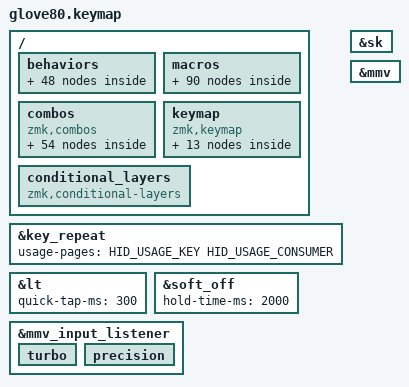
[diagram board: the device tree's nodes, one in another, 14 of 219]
/*
 * Copyright (c) 2020 The ZMK Contributors
 *
 * SPDX-License-Identifier: MIT
 *  
 * Important notes, labels cannot be long
 */
// Mouse speed (precision mode divides by 3 via scaler)

#define ZMK_POINTING_DEFAULT_MOVE_VAL 500

#include <input/processors.dtsi>
#include <behaviors.dtsi>
#include <dt-bindings/zmk/bt.h>
#include <dt-bindings/zmk/keys.h>
#include <dt-bindings/zmk/outputs.h>
#include <dt-bindings/zmk/pointing.h>
#include <dt-bindings/zmk/rgb.h>

#define HYPER LC(LS(LG(LALT)))

// layers

&key_repeat { usage-pages = <HID_USAGE_KEY HID_USAGE_CONSUMER>; };

&sk {
    quick-release;
    release-after-ms = <2000>;
};

&lt { quick-tap-ms = <300>; };

&soft_off { hold-time-ms = <2000>; };

/ {
    behaviors {
        // For the "layer" key, it'd nice to be able to use it as either a shift or a toggle.
        // Configure it as a tap dance, so the first tap (or hold) is a &mo and the second tap is a &to

        magic: magic_hold_tap {
            compatible = "zmk,behavior-hold-tap";
            label = "MAGIC_HOLD_TAP";
            #binding-cells = <2>;
            flavor = "tap-preferred";
            tapping-term-ms = <200>;
            bindings = <&mo>, <&rgb_ug_status_macro>;
        };

        // Play / Next / Prev button

        play_next_prev_td: play_next_prev_td {
            compatible = "zmk,behavior-tap-dance";
            label = "PLAY_NEXT_PREV_TD";
            #binding-cells = <0>;
            bindings = <&kp C_PP>, <&kp C_NEXT>, <&kp C_PREV>;
        };

        // Caps word and dt for CAPSLOCK 
        /* Selection behaviours morphs
         *
         * This behaviours select text in a particular way.
         * They default to selecting to the right, but when shifted, they go to the left
         *
         * They depend on the 'selection' macros
         */

        select_word: select_word {
            compatible = "zmk,behavior-mod-morph";
            #binding-cells = <0>;
            label = "SELECT_WORD";
            bindings = <&select_word_right>, <&select_word_left>;

            mods = <(MOD_LSFT|MOD_RSFT)>;
        };

        extend_word: extend_word {
            compatible = "zmk,behavior-mod-morph";
            #binding-cells = <0>;
            bindings = <&extend_word_right>, <&extend_word_left>;

            mods = <(MOD_LSFT|MOD_RSFT)>;
        };

        extend_line: extend_line {
            compatible = "zmk,behavior-mod-morph";
            #binding-cells = <0>;
            bindings = <&extend_line_right>, <&extend_line_left>;

            mods = <(MOD_LSFT|MOD_RSFT)>;
        };

        select_line: select_line {
            compatible = "zmk,behavior-mod-morph";
            #binding-cells = <0>;
            bindings = <&select_line_right>, <&select_line_left>;

            mods = <(MOD_LSFT|MOD_RSFT)>;
        };

        sk_mo: sk_mo {
            compatible = "zmk,behavior-hold-tap";
            label = "SK_MO";
            bindings = <&mo>, <&sk>;

            #binding-cells = <2>;
            tapping-term-ms = <200>;
        };

        // 1t: selet all, 2t: cut all, 3t: copy all

        selec_all_copy_all_tp: selec_all_copy_all_tp {
            compatible = "zmk,behavior-tap-dance";
            label = "SELEC_ALL_COPY_ALL_TP";
            #binding-cells = <0>;
            bindings = <&kp LC(A)>, <&select_all_cut>, <&select_and_copy_all>;
        };

        // dt the ' to screenshot (convinient)
        // Hold like shift key, and tap to toggle it
        // 1t: show screen, 2t: toggle camera

        mst_show_screen_vid_td: mst_show_screen_vid_td {
            compatible = "zmk,behavior-tap-dance";
            label = "Show screen and toggle video";
            #binding-cells = <0>;
            bindings = <&mst_show_screen>, <&kp LS(LC(O))>;
        };

        // 1t: go to call window, 2t: answer call from toast, 3t: Call someone from the chat

        mst_call_cmds_td: mst_call_cmds_td {
            compatible = "zmk,behavior-tap-dance";
            label = "MST_CALL_CMDS_TD";
            #binding-cells = <0>;
            bindings = <&mst_go_mst_meeting>, <&mst_join_call>, <&kp LA(LS(A))>;
        };

        layer_mo_tog: layer_mo_tog {
            compatible = "zmk,behavior-hold-tap";
            label = "LAYER_MO_TOG";
            bindings = <&mo>, <&tog>;

            #binding-cells = <2>;
            tapping-term-ms = <200>;
            flavor = "balanced";
        };

        // 1t: reply to selcted message, 2t: reply to last message
        // 1t: react happy to selcted message, 2t: react happy to last message

        mst_react_td: mst_react_td {
            compatible = "zmk,behavior-tap-dance";
            label = "MST_REACT_TD";
            #binding-cells = <0>;
            bindings =
                <&mst_react_happy>,
                <&mst_react_heart>,
                <&mst_react_lol>,
                <&mst_react_surprise>;

            tapping-term-ms = <300>;
        };

        /* 
        * Home row mods
        *
        * This mods allow you to put modifiers in the home row, and be comfortable. Inspiration from: https://github.com/urob/zmk-config
        *
        * 1. Do not allow same hand mods (avoids collitions from the same hand)
        * 2. Quick tapping for tap hold behavior
        * 3. Hold trigger on release allows you to write fast without activating false positives
        *
        * There is a left and right version of the behaviour. You must put them accordingly
        */

        hrm_left: hrm_left {
            compatible = "zmk,behavior-hold-tap";
            label = "HRM_LEFT";
            bindings = <&kp>, <&kp>;

            #binding-cells = <2>;
            tapping-term-ms = <280>;
            quick-tap-ms = <200>;
            flavor = "balanced";
            require-prior-idle-ms = <175>;
            hold-trigger-key-positions = <55 56 57 72 73 74 40 58 28 16 6 7 8 9 18 19 20 21 30 31 32 33 42 43 44 45 60 61 62 63 76 77 78 79 5 6 17 18 29 30 41 42 59 60 75 76 52 53 54 70 71 69>;
            hold-trigger-on-release;
        };

        hrm_right: hrm_right {
            compatible = "zmk,behavior-hold-tap";
            label = "HRM_RIGHT";
            bindings = <&kp>, <&kp>;

            #binding-cells = <2>;
            tapping-term-ms = <280>;
            quick-tap-ms = <200>;
            flavor = "balanced";
            require-prior-idle-ms = <175>;
            hold-trigger-key-positions = <0 2 3 4 14 13 12 10 11 1 22 23 35 34 46 47 64 65 66 67 68 69 70 71 54 53 52 50 48 49 37 36 24 25 26 15 39 38 27 51 55 56 57 74 73 72>;
            hold-trigger-on-release;
        };

        // Similar to HRM but in thumbs for custom behaviour

        lt_thumbs_keys: lt_thumbs_keys {
            compatible = "zmk,behavior-hold-tap";
            label = "LT_THUMBS_KEYS";
            bindings = <&mo>, <&kp>;

            #binding-cells = <2>;
            tapping-term-ms = <175>;
            quick-tap-ms = <300>;
            flavor = "tap-preferred";
        };

        paste_copy_cut_td: paste_copy_cut_td {
            compatible = "zmk,behavior-tap-dance";
            label = "PASTE_COPY_CUT_TD";
            #binding-cells = <0>;
            bindings = <&paste>, <&copy>, <&cut>;
        };

        lock_td: lock_td {
            compatible = "zmk,behavior-tap-dance";
            label = "LOCK_TD";
            #binding-cells = <0>;
            bindings = <&kp LG(L)>, <&kp LG(ESCAPE)>;
        };

        vim_norm_delete: vim_norm_delete {
            compatible = "zmk,behavior-tap-dance";
            label = "VIM_NORM_DELETE";
            #binding-cells = <0>;
            bindings = <&kp DELETE>, <&del_line>;
        };

        vim_norm_a: vim_norm_a {
            compatible = "zmk,behavior-mod-morph";
            label = "VIM_NORM_A";
            bindings = <&vim_kp_exit_norm RIGHT>, <&vim_kp_exit_norm END>;

            #binding-cells = <0>;
            mods = <(MOD_RSFT|MOD_LSFT)>;
        };

        vim_norm_i: vim_norm_i {
            compatible = "zmk,behavior-mod-morph";
            label = "VIM_NORM_I";
            bindings = <&tog 0>, <&vim_kp_exit_norm HOME>;

            #binding-cells = <0>;
            mods = <(MOD_RSFT|MOD_LSFT)>;
        };

        vim_norm_c: vim_norm_c {
            compatible = "zmk,behavior-mod-morph";
            label = "VIM_NORM_C";
            bindings = <&vim_norm_c_inner_word>, <&vim_c_del_line>;

            #binding-cells = <0>;
            mods = <(MOD_RSFT|MOD_LSFT)>;
        };

        vim_norm_v: vim_norm_v {
            compatible = "zmk,behavior-mod-morph";
            label = "VIM_NORM_V";
            bindings = <&vim_norm_v_kp>, <&vim_norm_V_kp>;

            #binding-cells = <0>;
            mods = <(MOD_RSFT|MOD_LSFT)>;
        };

        app_switcher_td: app_switcher_td {
            compatible = "zmk,behavior-tap-dance";
            label = "APP_SWITCHER_TD";
            #binding-cells = <0>;
            bindings = <&app_switcher>, <&app_switcher_killer>;
        };

        sk_shift_caps_word_caps_td: sk_shift_caps_word_caps_td {
            compatible = "zmk,behavior-tap-dance";
            label = "SK_SHIFT_CAPS_WORD_CAPS_TD";
            #binding-cells = <0>;
            bindings = <&sk RIGHT_SHIFT>, <&caps_word>, <&kp CAPSLOCK>;
        };

        better_slash: better_slash {
            compatible = "zmk,behavior-mod-morph";
            label = "BETTER_SLASH";
            bindings = <&kp SLASH>, <&kp BACKSLASH>;

            #binding-cells = <0>;
            mods = <(MOD_LALT|MOD_RALT)>;
        };

        // Shift HRM: faster timing (175ms vs 200ms) because index fingers naturally move faster
        // than other fingers. Lower require-prior-idle (150ms) for same reason.

        hmr_shift_left: hmr_shift_left {
            compatible = "zmk,behavior-hold-tap";
            label = "HMR_SHIFT_LEFT";
            bindings = <&kp>, <&kp>;

            #binding-cells = <2>;
            tapping-term-ms = <200>;
            quick-tap-ms = <175>;
            flavor = "balanced";
            require-prior-idle-ms = <150>;
            hold-trigger-key-positions = <55 56 57 72 73 74 40 58 28 16 6 7 8 9 18 19 20 21 30 31 32 33 42 43 44 45 60 61 62 63 76 77 78 79 5 6 17 18 29 30 41 42 59 60 75 76 52 53 54 70 71 69>;
            hold-trigger-on-release;
        };

        hmr_shift_right: hmr_shift_right {
            compatible = "zmk,behavior-hold-tap";
            label = "HMR_SHIFT_RIGHT";
            bindings = <&kp>, <&kp>;

            #binding-cells = <2>;
            tapping-term-ms = <200>;
            quick-tap-ms = <175>;
            flavor = "balanced";
            require-prior-idle-ms = <150>;
            hold-trigger-key-positions = <55 56 57 72 73 74 52 53 54 70 71 69 0 1 2 3 4 10 11 12 13 14 15 22 23 24 25 26 27 34 35 36 37 38 39 46 47 48 49 50 51 52 53 54 64 65 66 67 68 69 70 71>;
            hold-trigger-on-release;
        };

        mst_goback_call_mt: mst_goback_call_mt {
            compatible = "zmk,behavior-hold-tap";
            label = "MST_GOBACK_CALL_MT";
            bindings = <&go_call_unmute_mute_go_back>, <&kp>;

            #binding-cells = <2>;
            flavor = "tap-preferred";
            tapping-term-ms = <125>;
        };

        mst_chatlist_go_unread_mute_td: mst_chatlist_go_unread_mute_td {
            compatible = "zmk,behavior-tap-dance";
            label = "MST_CHATLIST_GO_UNREAD_MUTE_TD";
            #binding-cells = <0>;
            bindings =
                <&kp LC(L)>,
                <&mst_tog_unread_chat>,
                <&mst_tog_mute_chat>;

            tapping-term-ms = <300>;
        };

        hold_bt_0: hold_bt_0 {
            compatible = "zmk,behavior-hold-tap";
            label = "HOLD_BT_0";
            bindings = <&bt_0>, <&kp>;

            #binding-cells = <2>;
            tapping-term-ms = <200>;
            quick-tap-ms = <300>;
            require-prior-idle-ms = <200>;
            flavor = "tap-preferred";
        };

        hold_bt_2: hold_bt_2 {
            compatible = "zmk,behavior-hold-tap";
            label = "HOLD_BT_2";
            bindings = <&bt_2>, <&kp>;

            #binding-cells = <2>;
            tapping-term-ms = <200>;
            quick-tap-ms = <300>;
            require-prior-idle-ms = <200>;
            flavor = "tap-preferred";
        };

        hold_bt_1: hold_bt_1 {
            compatible = "zmk,behavior-hold-tap";
            label = "HOLD_BT_1";
            bindings = <&bt_1>, <&kp>;

            #binding-cells = <2>;
            tapping-term-ms = <200>;
            quick-tap-ms = <300>;
            require-prior-idle-ms = <200>;
            flavor = "tap-preferred";
        };

        lpar_lt: lpar_lt {
            compatible = "zmk,behavior-mod-morph";
            label = "LPAR_LT";
            bindings = <&kp LEFT_PARENTHESIS>, <&kp LESS_THAN>;

            #binding-cells = <0>;
            mods = <(MOD_LSFT|MOD_RSFT)>;
        };

        rpar_gt: rpar_gt {
            compatible = "zmk,behavior-mod-morph";
            label = "RPAR_GT";
            bindings = <&kp RIGHT_PARENTHESIS>, <&kp GREATER_THAN>;

            #binding-cells = <0>;
            mods = <(MOD_LSFT|MOD_RSFT)>;
        };

        lbra_cur: lbra_cur {
            compatible = "zmk,behavior-mod-morph";
            label = "LBRA_CUR";
            bindings = <&kp LEFT_BRACKET>, <&kp LEFT_BRACE>;

            #binding-cells = <0>;
            mods = <(MOD_LSFT|MOD_RSFT)>;
        };

        rbra_cur: rbra_cur {
            compatible = "zmk,behavior-mod-morph";
            label = "RBRA_CUR";
            bindings = <&kp RIGHT_BRACKET>, <&kp RIGHT_BRACE>;

            #binding-cells = <0>;
            mods = <(MOD_LSFT|MOD_RSFT)>;
        };

        hrm_right_lpar: hrm_right_lpar {
            compatible = "zmk,behavior-hold-tap";
            label = "HRM_RIGHT_LPAR";
            bindings = <&kp>, <&lpar_lt>;

            #binding-cells = <2>;
            tapping-term-ms = <280>;
            quick-tap-ms = <200>;
            flavor = "balanced";
            require-prior-idle-ms = <150>;
            hold-trigger-key-positions = <0 2 3 4 14 13 12 10 11 1 22 23 35 34 46 47 64 65 66 67 68 69 70 71 54 53 52 50 48 49 37 36 24 25 26 15 39 38 27 51 55 56 57 74 73 72>;
            hold-trigger-on-release;
        };

        hrm_right_rpar: hrm_right_rpar {
            compatible = "zmk,behavior-hold-tap";
            label = "HRM_RIGHT_RPAR";
            bindings = <&kp>, <&rpar_gt>;

            #binding-cells = <2>;
            tapping-term-ms = <280>;
            quick-tap-ms = <200>;
            flavor = "balanced";
            require-prior-idle-ms = <150>;
            hold-trigger-key-positions = <0 2 3 4 14 13 12 10 11 1 22 23 35 34 46 47 64 65 66 67 68 69 70 71 54 53 52 50 48 49 37 36 24 25 26 15 39 38 27 51 55 56 57 74 73 72>;
            hold-trigger-on-release;
        };

        better_backspace: better_backspace {
            compatible = "zmk,behavior-mod-morph";
            label = "BETTER_BACKSPACE";
            bindings = <&kp BACKSPACE>, <&kp DELETE>;

            #binding-cells = <0>;
            mods = <(MOD_LSFT|MOD_RSFT)>;
            keep-mods = <(MOD_LSFT)>;
        };

        lt_thumb_backspace: lt_thumb_backspace {
            compatible = "zmk,behavior-hold-tap";
            label = "LT_THUMB_BACKSPACE";
            bindings = <&mo>, <&better_backspace>;

            #binding-cells = <2>;
            tapping-term-ms = <175>;
            quick-tap-ms = <300>;
            flavor = "tap-preferred";
        };

        better_space: better_space {
            compatible = "zmk,behavior-mod-morph";
            label = "BETTER_SPACE";
            bindings = <&kp SPACE>, <&auto_cap_dot>;

            #binding-cells = <0>;
            mods = <(MOD_LSFT)>;
            keep-mods = <(MOD_LCTL|MOD_LALT|MOD_LGUI|MOD_RCTL|MOD_RSFT|MOD_RALT|MOD_RGUI)>;
        };

        lt_thumb_better_space: lt_thumb_better_space {
            compatible = "zmk,behavior-hold-tap";
            label = "LT_THUMB_BETTER_SPACE";
            bindings = <&mo>, <&better_space>;

            #binding-cells = <2>;
            tapping-term-ms = <175>;
            quick-tap-ms = <300>;
            flavor = "tap-preferred";
        };

        copy_cut_td: copy_cut_td {
            compatible = "zmk,behavior-tap-dance";
            label = "COPY_CUT_TD";
            #binding-cells = <0>;
            bindings = <&copy>, <&cut>;
        };

        lt_thumb_gresc: lt_thumb_gresc {
            compatible = "zmk,behavior-hold-tap";
            label = "LT_THUMB_GRESC";
            bindings = <&mo>, <&gresc>;

            #binding-cells = <2>;
            tapping-term-ms = <175>;
            quick-tap-ms = <300>;
            flavor = "tap-preferred";
        };

        lt_thumb_shift_td: lt_thumb_shift_td {
            compatible = "zmk,behavior-hold-tap";
            label = "LT_THUMB_SHIFT_TD";
            bindings = <&mo>, <&sk_shift_caps_word_caps_td>;

            #binding-cells = <2>;
            tapping-term-ms = <175>;
            quick-tap-ms = <300>;
            flavor = "tap-preferred";
        };

        am_hrm_behaviour: am_hrm_behaviour {
            compatible = "zmk,behavior-hold-tap";
            label = "AM_HRM_BEHAVIOUR";
            bindings = <&kp>, <&hour_am>;

            #binding-cells = <2>;
            tapping-term-ms = <280>;
            quick-tap-ms = <200>;
            flavor = "balanced";
            require-prior-idle-ms = <150>;
            hold-trigger-key-positions = <55 56 57 72 73 74 40 58 28 16 6 7 8 9 18 19 20 21 30 31 32 33 42 43 44 45 60 61 62 63 76 77 78 79 5 6 17 18 29 30 41 42 59 60 75 76 52 53 54 70 71 69>;
            hold-trigger-on-release;
        };

        mst_gocall_goback_mt: mst_gocall_goback_mt {
            compatible = "zmk,behavior-hold-tap";
            label = "MST_GOCALL_GOBACK_MT";
            bindings = <&go_call_unmute_mute_go_back>, <&mst_go_call_unmute>;

            #binding-cells = <2>;
            flavor = "tap-preferred";
            tapping-term-ms = <125>;
        };

        mouse_gresc_td: mouse_gresc_td {
            compatible = "zmk,behavior-tap-dance";
            label = "MOUSE_GRESC_TD";
            #binding-cells = <0>;
            tapping-term-ms = <150>;
            bindings = <&lt_thumb_gresc 8 0>, <&tog 8>;
        };
    };

    macros {
        // Bluethoot profile macros, DO NOT TOUCH

        rgb_ug_status_macro: rgb_ug_status_macro_0 {
            label = "RGB_UG_STATUS";
            compatible = "zmk,behavior-macro";
            #binding-cells = <0>;
            bindings = <&rgb_ug RGB_STATUS>;
        };

        bt_0: bt_profile_macro_0 {
            label = "BT_0";
            compatible = "zmk,behavior-macro";
            #binding-cells = <0>;
            bindings = <&out OUT_BLE &bt BT_SEL 0>;
        };

        bt_1: bt_profile_macro_1 {
            label = "BT_1";
            compatible = "zmk,behavior-macro";
            #binding-cells = <0>;
            bindings = <&out OUT_BLE &bt BT_SEL 1>;
        };

        bt_2: bt_profile_macro_2 {
            label = "BT_2";
            compatible = "zmk,behavior-macro";
            #binding-cells = <0>;
            bindings = <&out OUT_BLE &bt BT_SEL 2>;
        };

        bt_3: bt_profile_macro_3 {
            label = "BT_3";
            compatible = "zmk,behavior-macro";
            #binding-cells = <0>;
            bindings = <&out OUT_BLE &bt BT_SEL 3>;
        };

        // Selection Macros

        select_none: select_none {
            label = "SN";
            compatible = "zmk,behavior-macro";
            #binding-cells = <0>;
            bindings = <&kp DOWN &kp UP &kp RIGHT &kp LEFT>;
        };

        select_word_right: select_word_right {
            compatible = "zmk,behavior-macro";
            label = "SELECT_WORD_RIGHT";
            #binding-cells = <0>;
            bindings = <&kp LC(RIGHT) &kp LC(LEFT) &kp LC(LS(RIGHT))>;
        };

        select_word_left: select_word_left {
            compatible = "zmk,behavior-macro";
            label = "SELECT_WORD_LEFT";
            #binding-cells = <0>;
            bindings = <&kp LC(LEFT_ARROW) &kp LC(RIGHT) &kp LC(LS(LEFT_ARROW))>;
        };

        extend_word_right: extend_word_right {
            compatible = "zmk,behavior-macro";
            #binding-cells = <0>;
            bindings = <&kp LS(LC(RIGHT))>;
            label = "EXTEND_WORD_RIGHT";
        };

        extend_word_left: extend_word_left {
            compatible = "zmk,behavior-macro";
            #binding-cells = <0>;
            bindings = <&kp LS(LC(LEFT_ARROW))>;
            label = "EXTEND_WORD_LEFT";
        };

        select_line_right: select_line_right {
            compatible = "zmk,behavior-macro";
            #binding-cells = <0>;
            bindings = <&kp HOME &kp LS(END)>;
            label = "SELECT_LINE_RIGHT";
        };

        select_line_left: select_line_left {
            compatible = "zmk,behavior-macro";
            #binding-cells = <0>;
            bindings = <&kp END &kp LS(HOME)>;
            label = "SELECT_LINE_LEFT";
        };

        extend_line_left: extend_line_left {
            compatible = "zmk,behavior-macro";
            #binding-cells = <0>;
            bindings = <&kp LS(UP) &kp LS(HOME)>;
            label = "EXTEND_LINE_LEFT";
        };

        extend_line_right: extend_line_right {
            compatible = "zmk,behavior-macro";
            #binding-cells = <0>;
            bindings = <&kp LS(DOWN) &kp LS(END)>;
            label = "EXTEND_LINE_RIGHT";
        };

        // Text manipulation

        undo: undo {
            compatible = "zmk,behavior-macro";
            #binding-cells = <0>;
            bindings = <&kp RC(Z)>;
            label = "UNDO";
        };

        redo: redo {
            compatible = "zmk,behavior-macro";
            #binding-cells = <0>;
            bindings = <&kp LC(Y)>;
            label = "REDO";
        };

        cut: cut {
            compatible = "zmk,behavior-macro";
            #binding-cells = <0>;
            bindings = <&kp LC(X)>;
            label = "CUT";
        };

        paste: paste {
            compatible = "zmk,behavior-macro";
            #binding-cells = <0>;
            bindings = <&kp LC(V)>;
            label = "PASTE";
        };

        copy: copy {
            compatible = "zmk,behavior-macro";
            #binding-cells = <0>;
            bindings = <&kp LC(C)>;
            label = "COPY";
        };

        my_email: my_email {
            compatible = "zmk,behavior-macro";
            #binding-cells = <0>;
            bindings = <&kp E &kp D &kp Y &kp G &kp O &kp M &kp E &kp Z &kp G &kp G &kp N4 &kp AT &kp G &kp M &kp A &kp I &kp L &kp DOT &kp C &kp O &kp M>;
            label = "MY_EMAIL";
        };

        win_desktop_right: win_right_desktop {
            compatible = "zmk,behavior-macro";
            #binding-cells = <0>;
            bindings = <&kp LC(LG(RIGHT))>;
            label = "WIN_RIGHT_DESKTOP";
        };

        win_desktop_left: win_desktop_left {
            compatible = "zmk,behavior-macro";
            #binding-cells = <0>;
            bindings = <&kp LC(LG(LEFT))>;
            label = "WIN_DESKTOP_LEFT";
        };

        close_app: close_app {
            compatible = "zmk,behavior-macro";
            #binding-cells = <0>;
            bindings = <&kp LA(F4)>;
            label = "CLOSE_APP";
        };

        select_and_copy_all: select_and_copy_all {
            compatible = "zmk,behavior-macro";
            #binding-cells = <0>;
            bindings = <&kp LC(A) &kp LC(C) &kp RIGHT>;
            label = "SELECT_AND_COPY_ALL";
        };

        select_all_cut: select_all_cut {
            compatible = "zmk,behavior-macro";
            #binding-cells = <0>;
            bindings = <&kp LC(A) &kp LC(X) &kp RIGHT>;
            label = "SELECT_ALL_CUT";
        };

        // Microsoft Teams (mst) layer macros

        mst_available: mst_available {
            compatible = "zmk,behavior-macro";
            #binding-cells = <0>;
            bindings =
                <&kp LC(E) &kp SLASH &kp A &kp V &kp A &kp I &kp L &kp A &kp B &kp L>,
                <&macro_wait_time 200>,
                <&kp E &kp ENTER>;

            label = "mst_AVAILABLE";
        };

        mst_busy: mst_busy {
            compatible = "zmk,behavior-macro";
            #binding-cells = <0>;
            bindings =
                <&kp LC(E) &kp SLASH &kp B &kp U &kp S>,
                <&macro_wait_time 200>,
                <&kp Y &kp ENTER>;

            label = "mst_BUSY";
        };

        mst_brb: mst_brb {
            compatible = "zmk,behavior-macro";
            #binding-cells = <0>;
            bindings =
                <&kp LC(E) &kp SLASH &kp B &kp R>,
                <&macro_wait_time 200>,
                <&kp B &kp ENTER>;

            label = "mst_BRB";
        };

        mst_offline: mst_offline {
            compatible = "zmk,behavior-macro";
            #binding-cells = <0>;
            bindings =
                <&kp LC(E) &kp SLASH &kp O &kp F &kp F &kp L &kp I &kp N>,
                <&macro_wait_time 200>,
                <&kp E &kp ENTER>;

            label = "mst_OFFLINE";
        };

        mst_away: mst_away {
            compatible = "zmk,behavior-macro";
            #binding-cells = <0>;
            bindings =
                <&kp LC(E) &kp SLASH &kp A &kp W &kp A>,
                <&macro_wait_time 200>,
                <&kp Y &kp ENTER>;

            label = "mst_AWAY";
        };

        mst_go_mst_meeting: mst_go_call {
            compatible = "zmk,behavior-macro";
            #binding-cells = <0>;
            bindings =
                <&kt LEFT_WIN>,
                <&macro_wait_time 100>,
                <&kp N1 &kp NUMBER_1 &kt LEFT_WIN>;

            label = "MST_GO_CALL";
        };

        mst_reply_current_msg: mst_reply_current_msg {
            compatible = "zmk,behavior-macro";
            #binding-cells = <0>;
            bindings = <&kp ENTER &kp LEFT &kp LEFT_ARROW &kp ENTER &tog 3>;
            label = "MST_REPLY_CURRENT_MSG";
        };

        mst_react_happy: mst_react_happy {
            compatible = "zmk,behavior-macro";
            #binding-cells = <0>;
            bindings = <&kp ENTER &kp ENTER &kp ESCAPE>;
            label = "MST_REACT_HAPPY";
        };

        mst_key_exit_mst: mst_key_exit_mst {
            compatible = "zmk,behavior-macro-one-param";
            #binding-cells = <1>;
            bindings = <&macro_param_1to1 &kp MACRO_PLACEHOLDER &tog 3>;
            label = "MST_KEY_EXIT_MST";
        };

        vim_kp_exit_norm: vim_to_insert {
            compatible = "zmk,behavior-macro-one-param";
            #binding-cells = <1>;
            bindings = <&macro_param_1to1 &kp MACRO_PLACEHOLDER &tog 0>;
            label = "VIM_TO_INSERT";
        };

        vim_exit_visual_kp: vim_tog_visual {
            compatible = "zmk,behavior-macro-one-param";
            #binding-cells = <1>;
            bindings = <&kt LEFT_SHIFT &macro_param_1to1 &kp MACRO_PLACEHOLDER &tog 0 &kp RIGHT &kp LEFT_ARROW>;
            label = "VIM_TOG_VISUAL";
        };

        vim_norm_v_kp: vim_enter_visual {
            compatible = "zmk,behavior-macro";
            #binding-cells = <0>;
            bindings = <&tog 0 &kt LEFT_SHIFT>;
            label = "VIM_ENTER_VISUAL";
        };

        mst_go_to_teams: mst_go_to_teams {
            compatible = "zmk,behavior-macro";
            #binding-cells = <0>;
            bindings =
                <&macro_wait_time 100>,
                <&macro_press>,
                <&kp LEFT_WIN>,
                <&macro_tap>,
                <&kp NUMBER_1>,
                <&macro_release>,
                <&kp LEFT_WIN>;

            label = "MST_GO_TO_TEAMS";
        };

        two_kp: dt_kp {
            compatible = "zmk,behavior-macro-two-param";
            #binding-cells = <2>;
            bindings = <&macro_param_1to1 &kp MACRO_PLACEHOLDER &macro_param_2to1 &kp MACRO_PLACEHOLDER>;
            label = "DT_KP";
        };

        del_line: del_line {
            compatible = "zmk,behavior-macro";
            #binding-cells = <0>;
            bindings = <&kp HOME &kp LS(END) &kp LC(X)>;
            label = "DEL_LINE";
        };

        copy_line: copy_line {
            compatible = "zmk,behavior-macro";
            #binding-cells = <0>;
            bindings = <&kp HOME &kp LS(END) &kp LC(C) &kp END>;
            label = "COPY_LINE";
        };

        mo_w_glow: mo_w_glow {
            compatible = "zmk,behavior-macro-two-param";
            #binding-cells = <2>;
            bindings =
                <&macro_wait_time 50>,
                <&macro_tap_time 0>,
                <&macro_press>,
                <&macro_param_1to1 &mo MACRO_PLACEHOLDER>,
                <&macro_tap>,
                <&macro_param_2to2 &rgb_ug RGB_COLOR_HSB_CMD MACRO_PLACEHOLDER>,
                <&macro_pause_for_release>,
                <&macro_release>,
                <&macro_param_1to1 &mo MACRO_PLACEHOLDER>,
                <&macro_tap>,
                <&rgb_ug RGB_OFF>;

            label = "MO_W_GLOW";
        };

        vim_exit_visual_and_norm: vim_exit_visual_norm {
            compatible = "zmk,behavior-macro-one-param";
            #binding-cells = <1>;
            bindings = <&kt LEFT_SHIFT &macro_param_1to1 &kp MACRO_PLACEHOLDER &tog 0 &tog 0 &kp RIGHT &kp LEFT_ARROW>;
            label = "VIM_EXIT_VISUAL_NORM";
        };

        vim_copy_kp: vim_copy_kp {
            compatible = "zmk,behavior-macro";
            #binding-cells = <0>;
            bindings = <&kp LC(C) &kp ESCAPE>;
            label = "VIM_COPY_KP";
        };

        vim_o_kp: vim_o_kp {
            compatible = "zmk,behavior-macro";
            #binding-cells = <0>;
            bindings = <&kp END &kp ENTER &tog 0>;
            label = "VIM_O_KP";
        };

        vim_c_del_line: vim_c_del_line {
            compatible = "zmk,behavior-macro";
            #binding-cells = <0>;
            bindings = <&kp LS(DOWN) &kp LS(END) &kp DEL &tog 0>;
            label = "VIM_C_DEL_LINE";
        };

        vim_norm_c_inner_word: vim_norm_c_inner_word {
            compatible = "zmk,behavior-macro";
            #binding-cells = <0>;
            bindings =
                <&macro_wait_time 100>,
                <&select_word_right &kp DELETE &tog 0>;

            label = "VIM_NORM_C_INNER_WORD";
        };

        vim_norm_V_kp: vim_V_kp {
            compatible = "zmk,behavior-macro";
            #binding-cells = <0>;
            bindings =
                <&tog 0>,
                <&macro_wait_time 100>,
                <&kp HOME>,
                <&macro_wait_time 30>,
                <&kt LEFT_SHIFT &kp END>;

            label = "VIM_V_KP";
        };

        app_switcher: app_switcher {
            compatible = "zmk,behavior-macro";
            #binding-cells = <0>;
            bindings =
                <&macro_press>,
                <&kp LEFT_ALT>,
                <&macro_tap>,
                <&kp TAB>,
                <&macro_pause_for_release>,
                <&macro_release>,
                <&kp LEFT_ALT>;

            label = "APP_SWITCHER";
        };

        mst_join_call: mst_join_call {
            compatible = "zmk,behavior-macro";
            #binding-cells = <0>;
            bindings =
                <&macro_wait_time 2000>,
                <&kp LC(LS(J))>,
                <&macro_wait_time 200>,
                <&macro_press>,
                <&kp LEFT_SHIFT>,
                <&macro_tap>,
                <&kp TAB &kp TAB &kp TAB>,
                <&macro_release>,
                <&kp LEFT_SHIFT>,
                <&macro_tap>,
                <&kp ENTER>;

            label = "MST_JOIN_CALL";
        };

        app_switcher_killer: app_switcher_killer {
            compatible = "zmk,behavior-macro";
            #binding-cells = <0>;
            bindings =
                <&macro_press>,
                <&kp LEFT_ALT>,
                <&macro_tap>,
                <&kp TAB>,
                <&macro_pause_for_release>,
                <&macro_wait_time 100>,
                <&macro_release>,
                <&kp LEFT_ALT>,
                <&macro_tap>,
                <&close_app>;

            label = "APP_SWITCHER_KILLER";
        };

        vim_exit_visual: vim_exit_visual {
            compatible = "zmk,behavior-macro";
            #binding-cells = <0>;
            bindings = <&kt LEFT_SHIFT &tog 0>;
            label = "VIM_EXIT_VISUAL";
        };

        full_screen_window: full_screen_window {
            compatible = "zmk,behavior-macro";
            #binding-cells = <0>;
            bindings =
                <&macro_wait_time 200>,
                <&macro_press>,
                <&kp LEFT_GUI>,
                <&macro_tap>,
                <&kp UP_ARROW &kp UP_ARROW &kp DOWN &kp UP_ARROW>,
                <&macro_release>,
                <&kp LEFT_GUI>;

            label = "FULL_SCREEN_WINDOW";
        };

        go_call_unmute_mute_go_back: go_call_unmute_mute_go_back {
            compatible = "zmk,behavior-macro";
            #binding-cells = <0>;
            bindings =
                <&mst_go_mst_meeting>,
                <&macro_wait_time 30>,
                <&macro_press>,
                <&kp LC(LS(M))>,
                <&macro_pause_for_release>,
                <&macro_release>,
                <&kp LC(LS(M))>,
                <&macro_tap>,
                <&kp LA(TAB)>;

            label = "GO_CALL_UNMUTE_MUTE_GO_BACK";
        };

        mst_tog_unread_chat: mst_tog_red_chat {
            compatible = "zmk,behavior-macro";
            #binding-cells = <0>;
            bindings = <&macro_wait_time 60>, <&kp K_APP &kp DOWN &kp ENTER>;

            label = "MST_TOG_RED_CHAT";
        };

        mst_tog_mute_chat: mst_tog_chat_mute {
            compatible = "zmk,behavior-macro";
            #binding-cells = <0>;
            bindings =
                <&macro_wait_time 60>,
                <&kp K_APP &kp DOWN &kp DOWN &kp DOWN &kp ENTER>;

            label = "MST_TOG_CHAT_MUTE";
        };

        win_move_screen_left: win_move_screen_left {
            compatible = "zmk,behavior-macro";
            #binding-cells = <0>;
            bindings = <&kp LG(LS(LEFT))>;
            label = "WIN_MOVE_SCREEN_LEFT";
        };

        win_move_screen_right: win_move_screen_right {
            compatible = "zmk,behavior-macro";
            #binding-cells = <0>;
            bindings = <&kp LG(LS(RIGHT))>;
            label = "WIN_MOVE_SCREEN_RIGHT";
        };

        mute_and_lock: mute_and_lock {
            compatible = "zmk,behavior-macro";
            #binding-cells = <0>;
            bindings = <&kp C_MUTE &kp K_LOCK &kp LG(L)>;
            label = "MUTE_AND_LOCK";
        };

        better_delimiter: better_delimiter {
            compatible = "zmk,behavior-macro-two-param";
            #binding-cells = <2>;
            bindings = <&macro_param_1to1 &kp MACRO_PLACEHOLDER &macro_param_2to1 &kp MACRO_PLACEHOLDER &kp LEFT>;
            label = "BETTER_DELIMITER";
        };

        go_temp_mst: go_temp_mst {
            compatible = "zmk,behavior-macro";
            #binding-cells = <0>;
            bindings =
                <&mst_go_to_teams>,
                <&macro_wait_time 30>,
                <&to 3>,
                <&macro_pause_for_release>,
                <&tog 3 &kp LA(TAB)>;

            label = "GO_TEMP_MST";
        };

        auto_cap_dot: auto_cap_dot {
            compatible = "zmk,behavior-macro";
            #binding-cells = <0>;
            bindings = <&kp DOT &kp SPACE &sk LEFT_SHIFT>;
            label = "AUTO_CAP_DOT";
        };

        windows_shutdown: windows_shutdown {
            compatible = "zmk,behavior-macro";
            #binding-cells = <0>;
            bindings =
                <&macro_wait_time 500>,
                <&macro_tap_time 50>,
                <&kp LG(X) &kp U &kp U>;

            label = "WINDOWS_SHUTDOWN";
        };

        mst_react_lol: mst_react_lol {
            compatible = "zmk,behavior-macro";
            #binding-cells = <0>;
            bindings = <&kp ENTER &kp RIGHT &kp RIGHT &kp ENTER &kp ESCAPE>;
            label = "MST_REACT_LOL";
        };

        mst_react_surprise: mst_react_surprise {
            compatible = "zmk,behavior-macro";
            #binding-cells = <0>;
            bindings = <&kp ENTER &kp RIGHT &kp RIGHT &kp RIGHT &kp ENTER &kp ESCAPE>;
            label = "MST_REACT_SURPRISE";
        };

        mst_react_more: mst_react_more {
            compatible = "zmk,behavior-macro";
            #binding-cells = <0>;
            bindings = <&kp ENTER &kp RIGHT &kp RIGHT &kp RIGHT &kp RIGHT &kp ENTER &tog 3>;
            label = "MST_REACT_MORE";
        };

        mst_show_screen: mst_show_screen {
            compatible = "zmk,behavior-macro";
            #binding-cells = <0>;
            bindings =
                <&macro_wait_time 1750>,
                <&kp LC(LS(E))>,
                <&macro_wait_time 200>,
                <&kp TAB &kp TAB &kp TAB &tog 3>;

            label = "MST_SHOW_SCREEN";
        };

        mst_react_heart: mst_react_heart {
            compatible = "zmk,behavior-macro";
            #binding-cells = <0>;
            bindings = <&kp ENTER &kp RIGHT &kp ENTER &kp ESCAPE>;
            label = "MST_REACT_HEART";
        };

        enie_numpad: enie_numpad {
            compatible = "zmk,behavior-macro";
            #binding-cells = <0>;
            bindings =
                <&macro_wait_time 10>,
                <&macro_press>,
                <&kp LEFT_ALT>,
                <&macro_tap>,
                <&kp KP_NUMBER_1 &kp KP_NUMBER_6 &kp KP_NUMBER_4>,
                <&macro_release>,
                <&kp LALT>;

            label = "ENIE_NUMPAD";
        };

        surround_block_quotes: surround_block_quotes {
            compatible = "zmk,behavior-macro";
            #binding-cells = <0>;
            bindings = <&kp DOUBLE_QUOTES &kp DOUBLE_QUOTES &kp DOUBLE_QUOTES &kp ENTER &kp ENTER &kp DOUBLE_QUOTES &kp DOUBLE_QUOTES &kp DOUBLE_QUOTES &kp UP_ARROW>;
            label = "SURROUND_BLOCK_QUOTES";
        };

        surround_block_grave: surround_block_back {
            compatible = "zmk,behavior-macro";
            #binding-cells = <0>;
            bindings = <&kp GRAVE &kp GRAVE &kp GRAVE &kp ENTER &kp ENTER &kp GRAVE &kp GRAVE &kp GRAVE &kp UP_ARROW>;
            label = "SURROUND_BLOCK_BACK";
        };

        hour_am: hour_am {
            compatible = "zmk,behavior-macro";
            #binding-cells = <0>;
            bindings = <&kp A &kp M>;
            label = "HOUR_AM";
        };

        tmux_prefix: tmux_prefix {
            compatible = "zmk,behavior-macro";
            #binding-cells = <0>;
            bindings = <&kp LC(SPACE)>;
            label = "TMUX_PREFIX";
        };

        mst_go_call_unmute: go_call_unmute {
            compatible = "zmk,behavior-macro";
            #binding-cells = <0>;
            bindings =
                <&mst_go_mst_meeting>,
                <&macro_wait_time 30>,
                <&kp LC(LS(M))>;

            label = "GO_CALL_UNMUTE";
        };

        // MuseScore (ms_) macros
        // MuseScore uses same shortcuts as generic: undo=LC(Z), redo=LC(LS(Z)), copy/paste/cut=LC(C/V/X)
        // Using generic macros instead. ms_redo differs (LC(LS(Z)) vs LC(Y)) so keeping it.

        ms_redo: ms_redo {
            compatible = "zmk,behavior-macro";
            #binding-cells = <0>;
            bindings = <&kp LC(LS(Z))>;
            label = "MS_REDO";
        };

        ms_triplet: ms_triplet {
            compatible = "zmk,behavior-macro";
            #binding-cells = <0>;
            bindings = <&kp LC(N3)>;
            label = "MS_TRIPLET";
        };

        ms_add_bar: ms_add_bar {
            compatible = "zmk,behavior-macro";
            #binding-cells = <0>;
            bindings = <&kp LC(B)>;
            label = "MS_ADD_BAR";
        };

        ms_save: ms_save {
            compatible = "zmk,behavior-macro";
            #binding-cells = <0>;
            bindings = <&kp LC(S)>;
            label = "MS_SAVE";
        };

        ms_flip: ms_flip {
            compatible = "zmk,behavior-macro";
            #binding-cells = <0>;
            bindings = <&kp X>;
            label = "MS_FLIP";
        };

        ms_enhar: ms_enhar {
            compatible = "zmk,behavior-macro";
            #binding-cells = <0>;
            bindings = <&kp J>;
            label = "MS_ENHAR";
        };

        ms_oct_up: ms_oct_up {
            compatible = "zmk,behavior-macro";
            #binding-cells = <0>;
            bindings = <&kp LC(UP_ARROW)>;
            label = "MS_OCT_UP";
        };

        ms_oct_dn: ms_oct_dn {
            compatible = "zmk,behavior-macro";
            #binding-cells = <0>;
            bindings = <&kp LC(DOWN_ARROW)>;
            label = "MS_OCT_DN";
        };

        ms_grace: ms_grace {
            compatible = "zmk,behavior-macro";
            #binding-cells = <0>;
            bindings = <&kp SLASH>;
            label = "MS_GRACE";
        };

        ms_accent: ms_accent {
            compatible = "zmk,behavior-macro";
            #binding-cells = <0>;
            bindings = <&kp LS(V)>;
            label = "MS_ACCENT";
        };

        ms_stacc: ms_stacc {
            compatible = "zmk,behavior-macro";
            #binding-cells = <0>;
            bindings = <&kp LS(S)>;
            label = "MS_STACC";
        };

        ms_slur: ms_slur {
            compatible = "zmk,behavior-macro";
            #binding-cells = <0>;
            bindings = <&kp S>;
            label = "MS_SLUR";
        };

        ms_tie: ms_tie {
            compatible = "zmk,behavior-macro";
            #binding-cells = <0>;
            bindings = <&kp T>;
            label = "MS_TIE";
        };

        ms_repeat: ms_repeat {
            compatible = "zmk,behavior-macro";
            #binding-cells = <0>;
            bindings = <&kp R>;
            label = "MS_REPEAT";
        };

        ms_halve: ms_halve {
            compatible = "zmk,behavior-macro";
            #binding-cells = <0>;
            bindings = <&kp Q>;
            label = "MS_HALVE";
        };

        ms_double: ms_double {
            compatible = "zmk,behavior-macro";
            #binding-cells = <0>;
            bindings = <&kp W>;
            label = "MS_DOUBLE";
        };
    };

    combos {
        // IMPORTANT NOTICE: This combos are based in QWERTY layout
        //
        // Combo timeout strategy:
        // - 18ms: tight combos on adjacent keys (home row, same finger column)
        // - 30ms: diagonal or cross-row combos where slight timing variance is expected
        // - 100ms+: deliberate multi-key chords (e.g., layer toggles) that should not fire accidentally

        compatible = "zmk,combos";

        // w + l (vim like) to switch to workspace in the right

        combo_win_desktop_right {
            bindings = <&win_desktop_right>;
            key-positions = <43 24>;
            require-prior-idle-ms = <100>;
        };

        // w + h (vim like) to switch to workspace in the left

        combo_win_desktop_left {
            bindings = <&win_desktop_left>;
            key-positions = <40 24>;
            require-prior-idle-ms = <100>;
        };

        // WIN + Q becomes ALT + F4 (closes any app)

        combo_alt_close_app {
            bindings = <&close_app>;
            key-positions = <44 23>;
            require-prior-idle-ms = <200>;
        };

        /*
        *
        * MST (Microsoft Teams) combos 
        *
        * This combos are available in the teams layer
        * */
        // j + k for putting available status
        // l + k for putting available brb
        // u+i This toggles temas layer. Available in base layer and teams layer for easy transitioning

        combo_toggle_teams {
            bindings = <&layer_mo_tog 3 3>;
            key-positions = <29 30 31>;
            layers = <0 3>;
            require-prior-idle-ms = <300>;
        };

        gaming_mode {
            bindings = <&tog 7>;
            key-positions = <50 48 37 69>;
            layers = <0>;
            require-prior-idle-ms = <500>;
        };

        combo_copy {
            bindings = <&copy_cut_td>;
            key-positions = <24 25>;
            require-prior-idle-ms = <200>;
            timeout-ms = <18>;
        };

        combo_paste {
            bindings = <&paste>;
            key-positions = <25 26>;
            require-prior-idle-ms = <200>;
            timeout-ms = <18>;
        };

        combo_go_meeting {
            bindings = <&mst_go_mst_meeting>;
            key-positions = <37 36>;
            layers = <3>;
            require-prior-idle-ms = <200>;
        };

        combo_go_teams {
            bindings = <&mst_go_to_teams>;
            key-positions = <38 37>;
            layers = <3>;
            require-prior-idle-ms = <200>;
        };

        combo_tilde {
            bindings = <&kp TILDE>;
            key-positions = <39 40>;
            layers = <0 4>;
            require-prior-idle-ms = <150>;
            timeout-ms = <18>;
        };

        combo_repeat_right {
            bindings = <&key_repeat>;
            key-positions = <30 41 43>;
        };

        combo_repeat_left {
            bindings = <&key_repeat>;
            key-positions = <38 39>;
        };

        combo_backspace_num {
            bindings = <&kp BACKSPACE>;
            key-positions = <41 42>;
            layers = <2>;
            require-prior-idle-ms = <150>;
            timeout-ms = <18>;
        };

        combo_space_num {
            bindings = <&kp SPACE>;
            key-positions = <42 43>;
            layers = <2>;
            require-prior-idle-ms = <150>;
            timeout-ms = <18>;
        };

        combo_quick_switch {
            bindings = <&app_switcher>;
            key-positions = <41 40>;
            require-prior-idle-ms = <150>;
            timeout-ms = <18>;
        };

        combo_undo {
            bindings = <&undo>;
            key-positions = <48 49>;
            require-prior-idle-ms = <150>;
            timeout-ms = <18>;
        };

        combo_symbols_space {
            bindings = <&kp SPACE>;
            key-positions = <36 37>;
            layers = <4>;
            require-prior-idle-ms = <150>;
            timeout-ms = <18>;
        };

        combo_symbols_backspace {
            bindings = <&kp BACKSPACE>;
            key-positions = <38 37>;
            layers = <4>;
            require-prior-idle-ms = <150>;
            timeout-ms = <18>;
        };

        combo_base_colon {
            bindings = <&kp COLON>;
            key-positions = <30 31>;
            layers = <0>;
            require-prior-idle-ms = <150>;
            timeout-ms = <18>;
        };

        combo_move_screen_left {
            bindings = <&kp LG(LS(LEFT))>;
            key-positions = <24 28>;
            require-prior-idle-ms = <150>;
            timeout-ms = <18>;
        };

        combo_move_screen_right {
            bindings = <&kp LG(LS(RIGHT))>;
            key-positions = <24 31>;
            require-prior-idle-ms = <100>;
            timeout-ms = <18>;
        };

        combo_full_screen {
            bindings = <&full_screen_window>;
            key-positions = <24 59>;
            require-prior-idle-ms = <100>;
            timeout-ms = <18>;
        };

        combo_better_double_quotes {
            bindings = <&better_delimiter DOUBLE_QUOTES DOUBLE_QUOTES>;
            key-positions = <29 26 25 30>;
            layers = <0>;
            require-prior-idle-ms = <150>;
            timeout-ms = <18>;
        };

        combo_better_quote {
            bindings = <&better_delimiter SINGLE_QUOTE SINGLE_QUOTE>;
            key-positions = <26 29>;
            layers = <0>;
            require-prior-idle-ms = <150>;
            timeout-ms = <18>;
        };

        combo_better_backtick {
            bindings = <&better_delimiter GRAVE GRAVE>;
            key-positions = <25 30>;
            layers = <0>;
            require-prior-idle-ms = <150>;
            timeout-ms = <18>;
        };

        combo_mute_and_lock {
            bindings = <&mute_and_lock>;
            key-positions = <69 74 37 42>;
            require-prior-idle-ms = <100>;
        };

        combo_lpar {
            bindings = <&hrm_right_lpar LS(LEFT_CONTROL) 0>;
            key-positions = <41 42>;
            layers = <0 4>;
            require-prior-idle-ms = <150>;
            timeout-ms = <18>;
        };

        combo_rpar {
            bindings = <&hrm_right_rpar LA(LEFT_CONTROL) 0>;
            key-positions = <42 43>;
            layers = <0 4>;
            require-prior-idle-ms = <150>;
            timeout-ms = <18>;
        };

        combo_lbra_cur {
            bindings = <&lbra_cur>;
            key-positions = <59 60>;
            layers = <0 4>;
            require-prior-idle-ms = <150>;
            timeout-ms = <18>;
        };

        combo_rbra_cur {
            bindings = <&rbra_cur>;
            key-positions = <60 61>;
            layers = <0 4>;
            require-prior-idle-ms = <150>;
            timeout-ms = <18>;
        };

        combo_tab {
            bindings = <&hrm_left LG(LEFT_ALT) TAB>;
            key-positions = <36 35>;
            timeout-ms = <18>;
            require-prior-idle-ms = <150>;
            layers = <0 4 3>;
        };

        combo_esc {
            bindings = <&kp ESC>;
            key-positions = <23 24>;
            timeout-ms = <18>;
            require-prior-idle-ms = <150>;
            layers = <0 4 3>;
        };

        combo_dash {
            bindings = <&hrm_left LS(LEFT_CONTROL) MINUS>;
            key-positions = <37 38>;
            timeout-ms = <18>;
            require-prior-idle-ms = <150>;
            layers = <0 4 3>;
        };

        combo_underscore {
            bindings = <&kp UNDERSCORE>;
            key-positions = <49 37>;
            timeout-ms = <30>;
            require-prior-idle-ms = <50>;
            layers = <0 4 3>;
        };

        combo_dolar {
            bindings = <&kp DOLLAR>;
            key-positions = <38 26>;
            timeout-ms = <30>;
            require-prior-idle-ms = <50>;
            layers = <0 4 3>;
        };

        combo_hashtag {
            bindings = <&kp HASH>;
            key-positions = <25 37>;
            timeout-ms = <18>;
            require-prior-idle-ms = <150>;
            layers = <0 4 3>;
        };

        combo_at {
            bindings = <&kp AT_SIGN>;
            key-positions = <24 36>;
            timeout-ms = <30>;
            require-prior-idle-ms = <50>;
            layers = <0 4 3>;
        };

        combo_slash {
            bindings = <&better_slash>;
            key-positions = <61 43>;
            timeout-ms = <30>;
            require-prior-idle-ms = <50>;
            layers = <0 4 3>;
        };

        combo_pipe {
            bindings = <&kp PIPE>;
            key-positions = <62 44>;
            timeout-ms = <30>;
            require-prior-idle-ms = <50>;
            layers = <0 4 3>;
        };

        combo_tog_teams_left {
            bindings = <&tog 3>;
            key-positions = <69 25>;
            layers = <3 0>;
            timeout-ms = <100>;
            require-prior-idle-ms = <15>;
        };

        combo_percent {
            bindings = <&kp PERCENT>;
            key-positions = <50 38>;
            timeout-ms = <30>;
            require-prior-idle-ms = <50>;
            layers = <0 4>;
        };

        combo_enie {
            bindings = <&enie_numpad>;
            key-positions = <58 30>;
            timeout-ms = <18>;
            require-prior-idle-ms = <150>;
            layers = <0>;
        };

        combo_caret {
            bindings = <&kp CARET>;
            key-positions = <23 35>;
            timeout-ms = <30>;
            require-prior-idle-ms = <50>;
            layers = <0 4 3>;
        };

        combo_plus {
            bindings = <&kp PLUS>;
            key-positions = <35 47>;
            timeout-ms = <30>;
            require-prior-idle-ms = <50>;
            layers = <0 4>;
        };

        combo_ampersand {
            bindings = <&kp AMPERSAND>;
            key-positions = <48 36>;
            timeout-ms = <30>;
            require-prior-idle-ms = <50>;
            layers = <0 4>;
        };

        combo_star {
            bindings = <&kp LS(ASTERISK)>;
            key-positions = <26 27>;
            timeout-ms = <18>;
            require-prior-idle-ms = <150>;
            layers = <0 4 3>;
        };

        combo_dquotes {
            bindings = <&kp DOUBLE_QUOTES>;
            key-positions = <29 41>;
            timeout-ms = <30>;
            require-prior-idle-ms = <50>;
            layers = <0 4 3>;
        };

        combo_question {
            bindings = <&kp RS(QUESTION)>;
            key-positions = <42 30>;
            timeout-ms = <30>;
            require-prior-idle-ms = <50>;
            layers = <0 4 3>;
        };

        combo_exclamation {
            bindings = <&kp RS(EXCLAMATION)>;
            key-positions = <31 43>;
            timeout-ms = <30>;
            require-prior-idle-ms = <50>;
            layers = <0 4 3>;
        };

        combo_single_number {
            bindings = <&sl 2>;
            key-positions = <69 70>;
            layers = <0>;
        };

        combo_single_symbol {
            bindings = <&sl 4>;
            key-positions = <73 74>;
            layers = <0>;
        };

        combo_enie_one_finger {
            bindings = <&enie_numpad>;
            key-positions = <32 44>;
            timeout-ms = <18>;
            require-prior-idle-ms = <150>;
            layers = <0>;
        };

        combo_block_quote {
            bindings = <&surround_block_quotes>;
            key-positions = <29 17>;
            timeout-ms = <30>;
            require-prior-idle-ms = <50>;
            layers = <0 4 3>;
        };

        combo_block_back {
            bindings = <&surround_block_grave>;
            key-positions = <45 33>;
            timeout-ms = <30>;
            require-prior-idle-ms = <50>;
            layers = <0 4>;
        };
    };

    keymap {
        compatible = "zmk,keymap";

        base_layer {
            // ---------------------------------------------------------------------------------------------------------------------------------
            // |  F1   |  F2 |  F3 |  F4  |  F5  |                                                               |  F6   |  F7   |  F8  |   F9  |  F10 |
            // |  =    |  1  |  2  |  3   |  4   |  5   |                                                 |  6   |   7   |   8   |  9   |   0   |   -  |
            // |  TAB  |  Q  |  W  |  E   |  R   |  T   |                                                 |  Y   |   U   |   I   |  O   |   P   |   \  |
            // |  ESC  |  A  |  S  |  D   |  F   |  G   |                                                 |  H   |   J   |   K   |  L   |   ;   |   '  |
            // |   `   |  Z  |  X  |  C   |  V   |  B   | LSHFT | LCTRL | LOWER | | LGUI  | RCTRL | RSHFT |  N   |   M   |   ,   |  .   |   /   | PGUP |
            // | MAGIC | HOME| END | LEFT | RIGHT|      | BSPC  | DEL   | LALT  | | RALT  | RET   | SPACE |      |  UP   | DOWN  |  [   |   ]   | PGDN |

            bindings = <
&tog 8         &kp C_MUTE             &kp C_VOL_DN           &tog 12                   &kp LC(LS(ESCAPE))                                                                                                                                                                                                                   &kp LG(P)                                             &play_next_prev_td                            &kp LG(E)                                 &kp C_BRIGHTNESS_INC                      &kp C_BRIGHTNESS_DEC
&undo          &hold_bt_1 0 NUMBER_1  &hold_bt_2 0 NUMBER_2  &mt PRINTSCREEN NUMBER_3  &kp NUMBER_4                  &mst_goback_call_mt 0 N5                                                                                                                                                   &mt C_VOLUME_DOWN NUMBER_6  &mt C_VOLUME_UP N7                                    &mt C_MUTE N8                                 &mt C_BRIGHTNESS_INC N9                   &hold_bt_0 0 N0                           &enie_numpad
&kp TAB        &kp Q                  &hrm_left RIGHT_ALT W  &kp E                     &kp R                         &kp T                                                                                                                                                                      &kp Y                       &kp U                                                 &kp I                                         &hrm_right RIGHT_ALT O                    &kp P                                     &kp GRAVE
&kp EQUAL      &hrm_left LEFT_GUI A   &hrm_left LEFT_ALT S   &hrm_left LEFT_CONTROL D  &hmr_shift_left LEFT_SHIFT F  &kp G                                                                                                                                                                      &kp H                       &hmr_shift_right RIGHT_SHIFT J                        &hrm_right RIGHT_CONTROL K                    &hrm_right LEFT_ALT L                     &hrm_right RIGHT_GUI SEMI                 &kp SQT
&kp LG(SPACE)  &kp Z                  &kp X                  &kp C                     &kp V                         &kp B                     &mouse_gresc_td          &lt 5 BACKSLASH         &my_email   &mst_gocall_goback_mt 0 0  &go_temp_mst                 &kp ENTER                   &kp N                       &kp M                                                 &kp COMMA                                     &kp DOT                                   &better_slash                             &tmux_prefix
&magic 11 0    &kp LG(PERIOD)         &kp LC(PG_UP)          &kp LC(PG_DN)             &full_screen_window                                     &lt_thumb_backspace 1 0  &lt_thumb_shift_td 2 0  &kp DELETE  &kp RIGHT_SHIFT            &sk_shift_caps_word_caps_td  &lt_thumb_better_space 4 0                              &better_delimiter LEFT_PARENTHESIS RIGHT_PARENTHESIS  &better_delimiter LEFT_BRACKET RIGHT_BRACKET  &better_delimiter LEFT_BRACE RIGHT_BRACE  &better_delimiter LESS_THAN GREATER_THAN  &magic 11 0
            >;
        };

        cursor_layer {
            bindings = <
&tog 1   &tog 1             &tog 1         &full_screen_window  &tog 1                                                                                                                                    &tog 1        &full_screen_window  &tog 1         &tog 1              &tog 1
&kp ESC  &kp RET            &kp K_APP      &kp LC(EQUAL)        &app_switcher_killer  &kp INSERT                                                                                             &kp INSERT   &kp LC(PLUS)  &kp LC(MINUS)        &kp K_APP      &kp RET             &kp ESC
&none    &layer_mo_tog 3 3  &redo          &undo                &app_switcher_td      &cut                                                                                                   &kp LG(TAB)  &kp LA(TAB)   &undo                &redo          &paste_copy_cut_td  &kp LC(K)
&none    &kp LGUI           &kp LALT       &kp LCTRL            &kp LEFT_SHIFT        &copy                                                                                                  &kp LEFT     &kp DOWN      &kp UP               &kp RIGHT      &kp BACKSPACE       &kp LC(L)
&none    &key_repeat        &kp SPACE      &kp ENTER            &kp BACKSPACE         &kp LG(PERIOD)  &kp LA(TAB)  &kp LG(TAB)  &kp TAB  &select_none            &extend_line  &extend_word  &kp HOME     &kp PG_DN     &kp PG_UP            &kp END        &kp LC(F)           &kp LC(J)
&trans   &win_desktop_left  &kp LC(PG_UP)  &kp LC(PG_DN)        &win_desktop_right                    &tog 1       &kp LC(TAB)  &tog 1   &selec_all_copy_all_tp  &select_line  &select_word               &kp LC(F)     &kp LC(G)            &kp LC(LS(G))  &kp LC(H)           &kp LG(DOT)
            >;
        };

        number_layer {
            bindings = <
&tog 2          &tog 2                        &tog 2        &tog 2            &tog 2                                                                                       &tog 2    &tog 2     &tog 2    &tog 2     &tog 2
&kp ESC         &kp RET                       &kp SPACE     &kp TAB           &kp DEL         &kp INSERT                                                        &kp CARET  &kp DLLR  &kp POUND  &kp AT    &kp EXCL   &kp PIPE
&none           &two_kp P M                   &redo         &undo             &kp X           &kp M                                                             &kp PRCNT  &kp N7    &kp N8     &kp N9    &kp COLON  &kp M
&kp KP_NUMLOCK  &am_hrm_behaviour LEFT_WIN A  &kp LEFT_ALT  &kp LEFT_CONTROL  &sk LEFT_SHIFT  &kp H                                                             &kp PLUS   &kp N4    &kp N5     &kp N6    &kp MINUS  &kp H
&none           &kp LC(A)                     &kp X         &kp TILDE         &kp UNDER       &kp MINUS   &kp D  &kp E   &kp F   &kp LT     &kp GT   &kp EQUAL  &kp STAR   &kp N1    &kp N2     &kp N3    &kp SLASH  &kp G
&trans          &none                         &extend_line  &extend_word      &kp BACKSPACE               &none  &tog 2  &tog 2  &kp COMMA  &kp DOT  &kp N0                &kp LPAR  &kp LBKT   &kp RBKT  &kp RPAR   &kp TILDE
            >;
        };

        teams_mst_layer {
            bindings = <
&tog 3     &tog 3                   &go_call_unmute_mute_go_back     &tog 3                   &tog 3                                                                                                                                                                                               &tog 3                  &tog 3                &tog 3             &tog 3                 &tog 3
&kp ENTER  &kp LC(N1)               &kp LC(N2)                       &kp LC(N3)               &kp LC(N4)               &kp LC(N5)                                                                                                                                          &kp LG(N1)              &kp LA(LS(EQUAL))       &kp LA(LS(MINUS))     &kp LA(LS(N0))     &none                  &none
&kp TAB    &kp LA(LS(N))            &mst_reply_current_msg           &mst_key_exit_mst LC(R)  &mst_react_td            &kp LC(LA(U))                                                                                                                                       &mst_react_more         &mst_react_happy        &mst_react_heart      &mst_react_lol     &mst_react_surprise    &mst_react_more
&kp ENTER  &kp LC(J)                &mst_chatlist_go_unread_mute_td  &kp UP                   &kp DOWN                 &kp LC(M)                                                                                                                                           &kp LS(LA(LEFT_ARROW))  &kp LS(LA(DOWN))        &kp LS(LA(UP_ARROW))  &kp LS(LA(RIGHT))  &none                  &kp ESCAPE
&none      &mst_key_exit_mst LC(E)  &mst_away                        &mst_brb                 &mst_available           &mst_offline   &mst_goback_call_mt 0 LC(LS(K))  &mst_show_screen_vid_td  &mst_call_cmds_td  &play_next_prev_td  &none              &tog 3           &kp LA(N5)              &kp LA(N1)              &kp LA(NUMBER_2)      &kp LA(NUMBER_3)   &kp LA(NUMBER_4)       &kp LA(NUMBER_6)
&trans     &mst_react_more          &full_screen_window              &mst_busy                &mst_key_exit_mst LC(F)                 &mt LC(SPACE) LS(LC(M))          &kp LC(LS(H))            &kp LS(LC(O))      &kp C_MUTE          &kp C_VOLUME_DOWN  &kp C_VOLUME_UP                          &win_move_screen_right  &none                 &none              &win_move_screen_left  &trans
            >;
        };

        symbols_layer {
            bindings = <
&tog 4         &tog 4          &tog 4         &tog 4             &tog 4                                                                                                                   &tog 4                &tog 4            &tog 4             &tog 4                 &tog 4
&none          &kp GRAVE       &kp SQT        &kp DOUBLE_QUOTES  &kp TILDE        &kp SEMICOLON                                                                            &none          &key_repeat           &undo             &none              &none                  &none
&kp LESS_THAN  &kp LEFT_BRACE  &lbra_cur      &rbra_cur          &kp RIGHT_BRACE  &kp GREATER_THAN                                                                         &kp SEMICOLON  &kp MINUS             &kp GREATER_THAN  &kp DOUBLE_QUOTES  &kp UNDERSCORE         &kp TILDE
&kp HASH       &kp CARET       &lpar_lt       &rpar_gt           &kp DOLLAR       &kp ASTERISK                                                                             &kp DOT        &kp LEFT_SHIFT        &kp LEFT_CONTROL  &kp LEFT_ALT       &kp LEFT_WIN           &kp SQT
&kp AT_SIGN    &kp PIPE        &kp EQUAL      &kp UNDERSCORE     &kp MINUS        &kp QUESTION      &kp NON_US_BACKSLASH  &kp TILDE  &key_repeat    &none   &none  &none   &kp COMMA      &kp SPACE             &kp BACKSPACE     &paste             &kp SLASH              &none
&trans         &kp TILDE       &kp AMPERSAND  &kp PLUS           &kp EXCLAMATION                    &kp PERCENT           &kp COLON  &kp SEMICOLON  &tog 4  &none  &tog 4                 &kp LEFT_PARENTHESIS  &kp LBKT          &kp RBKT           &kp RIGHT_PARENTHESIS  &trans
            >;
        };

        function_layer {
            bindings = <
&tog 11          &tog 11         &tog 11       &tog 11            &tog 11                                                                                                                                                  &tog 11                   &tog 11               &tog 11               &tog 11                   &tog 11
&none            &none           &none         &windows_shutdown  &none                         &none                                                                                        &none                         &kp LC(PLUS)              &kp LC(MINUS)         &kp LC(EQUAL)         &none                     &none
&kp PAUSE_BREAK  &kp SCROLLLOCK  &redo         &undo              &kp LS(LA(LC(LEFT_CONTROL)))  &kp PRINTSCREEN                                                                              &none                         &kp F7                    &kp F8                &kp F9                &kp F10                   &kp F13
&kp CAPS         &kp LEFT_WIN    &kp LEFT_ALT  &kp LEFT_CONTROL   &kp LEFT_SHIFT                &rgb_ug RGB_TOG                                                                              &kt LS(LA(LC(LEFT_CONTROL)))  &kp F4                    &kp F5                &kp F6                &kp F11                   &kp F14
&none            &kp KP_NUMLOCK  &none         &none              &none                         &kp K_SCREENSAVER  &none  &to 0  &none    &lock_td    &kp K_APPLICATION  &play_next_prev_td  &none                         &kp F1                    &kp F2                &kp F3                &kp F12                   &kp F15
&trans           &none           &none         &none              &none                                            &none  &none  &tog 11  &kp C_MUTE  &kp C_VOLUME_DOWN  &kp C_VOLUME_UP                                   &kp C_BRIGHTNESS_MAXIMUM  &kp C_BRIGHTNESS_INC  &kp C_BRIGHTNESS_DEC  &kp C_BRIGHTNESS_MINIMUM  &kp C_BRIGHTNESS_AUTO
            >;
        };

        gaming_layer {
            bindings = <
&tog 7     &tog 7     &tog 7  &tog 7  &tog 7                                                                                             &tog 7    &tog 7  &tog 7     &tog 7  &tog 7
&trans     &trans     &trans  &trans  &trans  &trans                                                                           &tog 7    &tog 7    &tog 7  &tog 7     &tog 7  &tog 7
&kp MINUS  &kp GRAVE  &kp B   &kp N   &kp M   &kp SQT                                                                          &kp J     &kp K     &kp I   &kp L      &tog 7  &tog 7
&kp T      &kp TAB    &kp Q   &kp W   &kp E   &kp R                                                                            &kp LEFT  &kp DOWN  &kp UP  &kp RIGHT  &tog 7  &tog 7
&kp G      &kp LSHFT  &kp A   &kp S   &kp D   &kp F    &kp ESC    &kp RET          &kp PAUSE_BREAK  &tog 7  &tog 7  &tog 7     &tog 7    &tog 7    &tog 7  &tog 7     &tog 7  &tog 7
&kp V      &kp LCTRL  &kp Z   &kp X   &kp C            &kp SPACE  &lt 11 LEFT_ALT  &kp LGUI         &tog 7  &tog 7  &kp SPACE            &tog 7    &tog 7  &tog 7     &tog 7  &tog 7
            >;
        };

        gaming_aux_layer {
            bindings = <
&trans  &trans        &trans        &trans        &trans                                                                              &trans  &trans  &trans  &trans  &trans
&trans  &trans        &trans        &trans        &trans        &trans                                                        &trans  &trans  &trans  &trans  &trans  &trans
&trans  &trans        &trans        &trans        &trans        &trans                                                        &trans  &trans  &trans  &trans  &trans  &trans
&trans  &trans        &kp CAPS      &key_repeat   &key_repeat   &trans                                                        &trans  &trans  &trans  &trans  &trans  &trans
&kp N9  &kp NUMBER_4  &kp NUMBER_3  &kp NUMBER_2  &kp NUMBER_1  &kp NUMBER_0  &trans  &trans  &trans  &trans  &trans  &trans  &trans  &trans  &trans  &trans  &trans  &trans
&trans  &kp N8        &kp N7        &kp NUMBER_6  &kp N5                      &trans  &trans  &trans  &trans  &trans  &trans          &trans  &trans  &trans  &trans  &trans
            >;
        };

        mouse_layer {
            // Left hand: home row = mods, R = precision hold, bottom row = clicks
            // Right hand: HJKL = movement, scroll around

            bindings = <
&tog 8  &none     &none      &none      &none                                                                                           &none           &none         &none            &none      &tog 8
&none   &none     &none      &none      &none       &none                                                               &none           &none           &none         &none            &none      &none
&none   &none     &none      &mo 10     &mo 9       &none                                                               &msc SCRL_LEFT  &msc SCRL_DOWN  &msc SCRL_UP  &msc SCRL_RIGHT  &none      &none
&none   &kp LGUI  &kp LALT   &kp LCTRL  &kp LSHIFT  &none                                                               &mmv MOVE_LEFT  &mmv MOVE_DOWN  &mmv MOVE_UP  &mmv MOVE_RIGHT  &mkp MCLK  &none
&none   &none     &mkp MCLK  &mkp RCLK  &mkp LCLK   &none  &to 0  &kp ESCAPE  &none  &mkp MCLK   &mo 9       &mkp LCLK  &mkp MB4        &mkp LCLK       &mkp RCLK     &mkp MB5         &none      &none
&none   &none     &none      &none      &none              &mo 9  &none       &none  &kp ESCAPE  &kp ESCAPE  &mkp RCLK                  &none           &none         &none            &none      &none
            >;
        };

        mouse_precision {
            bindings = <
&trans  &trans  &trans  &trans  &trans                                                                  &trans  &trans  &trans  &trans  &trans
&trans  &trans  &trans  &trans  &trans  &trans                                                  &trans  &trans  &trans  &trans  &trans  &trans
&trans  &trans  &trans  &none   &trans  &trans                                                  &trans  &trans  &trans  &trans  &trans  &trans
&trans  &trans  &trans  &trans  &trans  &trans                                                  &trans  &trans  &trans  &trans  &trans  &trans
&trans  &trans  &trans  &trans  &trans  &trans  &trans  &trans  &trans  &trans  &trans  &trans  &trans  &trans  &trans  &trans  &trans  &trans
&trans  &trans  &trans  &trans  &trans          &trans  &trans  &trans  &trans  &trans  &trans          &trans  &trans  &trans  &trans  &trans
            >;
        };

        mouse_turbo {
            bindings = <
&trans  &trans  &trans  &trans  &trans                                                                  &trans  &trans  &trans  &trans  &trans
&trans  &trans  &trans  &trans  &trans  &trans                                                  &trans  &trans  &trans  &trans  &trans  &trans
&trans  &trans  &trans  &trans  &none   &trans                                                  &trans  &trans  &trans  &trans  &trans  &trans
&trans  &trans  &trans  &trans  &trans  &trans                                                  &trans  &trans  &trans  &trans  &trans  &trans
&trans  &trans  &trans  &trans  &trans  &trans  &trans  &trans  &trans  &trans  &trans  &trans  &trans  &trans  &trans  &trans  &trans  &trans
&trans  &trans  &trans  &trans  &trans          &trans  &trans  &trans  &trans  &trans  &trans          &trans  &trans  &trans  &trans  &trans
            >;
        };

        magic_layer {
            bindings = <
&bt BT_CLR   &none                            &none                              &none                                       &none                                                                                                        &none                                     &none                             &none                             &none      &bt BT_CLR_ALL
&none        &none                            &none                              &none                                       &none            &none                                                                                &none  &none                                     &none                             &none                             &none      &none
&none        &rgb_ug RGB_SPI                  &rgb_ug RGB_SAI                    &rgb_ug RGB_HUI                             &rgb_ug RGB_BRI  &rgb_ug RGB_TOG                                                                      &none  &mo_w_glow 1 RGB_COLOR_HSB_VAL(0,100,50)  &rgb_ug RGB_COLOR_HSB(130,72,64)  &rgb_ug RGB_COLOR_HSB(0,0,100)    &none      &none
&bootloader  &rgb_ug RGB_SPD                  &rgb_ug RGB_SAD                    &rgb_ug RGB_HUD                             &rgb_ug RGB_BRD  &rgb_ug RGB_EFF                                                                      &none  &rgb_ug RGB_COLOR_HSB(288,100,64)         &rgb_ug RGB_COLOR_HSB(60,87,55)   &rgb_ug RGB_COLOR_HSB(0,0,0)      &none      &bootloader
&sys_reset   &rgb_ug RGB_COLOR_HSB(0,100,50)  &rgb_ug RGB_COLOR_HSB(125,100,50)  &mo_w_glow 1 RGB_COLOR_HSB_VAL(250,100,50)  &soft_off        &none            &bt_2  &bt_3  &none         &none  &none            &lock_td        &none  &rgb_ug RGB_COLOR_HSB(179,100,63)         &rgb_ug RGB_COLOR_HSB(29,100,53)  &rgb_ug RGB_COLOR_HSB(255,34,41)  &soft_off  &sys_reset
&none        &none                            &none                              &rgb_ug RGB_OFF                             &rgb_ug RGB_ON                    &bt_0  &bt_1  &out OUT_USB  &none  &rgb_ug RGB_OFF  &rgb_ug RGB_ON         &none                                     &none                             &none                             &none      &to 0
            >;
        };

        musescore_layer {
            bindings = <
&tog 12  &tog 12    &tog 12     &tog 12     &tog 12                                                                                       &tog 12  &tog 12  &tog 12  &tog 12  &tog 12
&none    &ms_save   &ms_flip    &ms_enhar   &ms_oct_up  &ms_oct_dn                                                               &tog 12  &tog 12  &tog 12  &tog 12  &tog 12  &tog 12
&none    &ms_slur   &ms_halve   &ms_double  &ms_repeat  &ms_tie                                                                  &tog 12  &tog 12  &tog 12  &tog 12  &tog 12  &tog 12
&kp DOT  &kp N3     &kp N4      &kp N5      &kp N6      &kp N7                                                                   &tog 12  &tog 12  &tog 12  &tog 12  &tog 12  &tog 12
&cut     &undo      &ms_redo    &copy       &paste      &ms_triplet  &kp ESC  &kp DEL    &ms_add_bar  &tog 12  &tog 12  &tog 12  &tog 12  &tog 12  &tog 12  &tog 12  &tog 12  &tog 12
&trans   &ms_grace  &ms_accent  &ms_stacc   &none                    &kp N0   &kp SPACE  &kp N        &tog 12  &tog 12  &tog 12           &tog 12  &tog 12  &tog 12  &tog 12  &trans
            >;
        };
    };

    conditional_layers { compatible = "zmk,conditional-layers"; };
};

// Mouse: constant speed (no acceleration), lower velocity for precision with keys

&mmv {
    time-to-max-speed-ms = <0>;
    acceleration-exponent = <0>;
};

// Precision mode: 1/3 speed when layer 9 (mouse_precision) is active
// Turbo mode: 8/5 speed (~800) when layer 10 (mouse_turbo) is active

&mmv_input_listener {
    turbo {
        layers = <10>;
        input-processors = <&zip_xy_scaler 8 5>;
    };
    precision {
        layers = <9>;
        input-processors = <&zip_xy_scaler 1 3>;
    };
};
